# HM1030 register map
File version: 0.1
Registers are 32-bit, read-write, reset 0x0 unless marked. A register's access mark holds for its fields unless they carry their own. Offsets are from the block's base; [hi:lo] are bit positions; lines under a group give offsets from that group; {n}, {i} and the like mark numbered series.

## DMA — Registers group
Base 0x40001000
0x00 DMA_CTR — DMA使能
  [0] DMA_EN
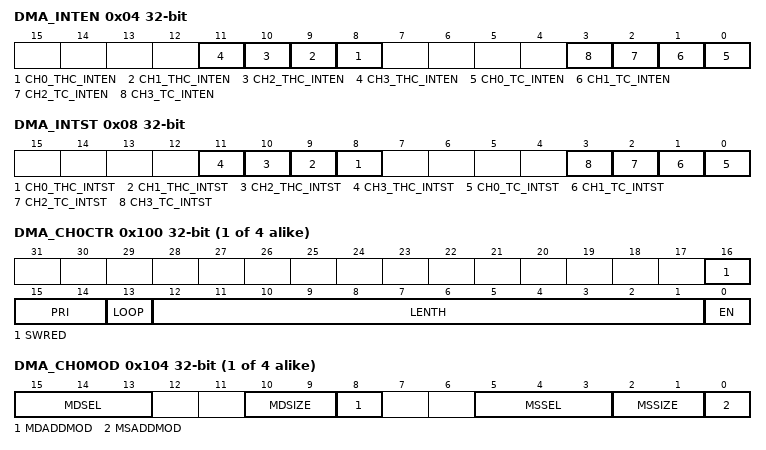
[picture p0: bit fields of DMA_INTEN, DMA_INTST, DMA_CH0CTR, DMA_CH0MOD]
0x04 DMA_INTEN — DMA中断使能
  [n+8] CH{n}_THC_INTEN (n=0..3) — 通道{n}传输一半完成中断使能寄存器
  [n] CH{n}_TC_INTEN (n=0..3) — 通道{n}传输完成中断使能寄存器
0x08 DMA_INTST — DMA中断状态
  [n+8] CH{n}_THC_INTST (n=0..3) — 通道{n}传输一半完成中断状态寄存器
  [n] CH{n}_TC_INTST (n=0..3) — 通道{n}传输完成中断状态寄存器
{0x100+0x20*i} DMA_CH{i}CTR (i=0..3) — DMA通道{i}控制寄存器
  [16] SWRED — 软件请求开始传输
  [15:14] PRI — 通道优先级
  [13] LOOP — 循环方式
  [12:1] LENTH — 传输计数
  [0] EN — 通道使能
{0x104+0x20*i} DMA_CH{i}MOD (i=0..3) — DMA通道{i}模式寄存器
  [15:13] MDSEL — MD测外设选择
  [10:9] MDSIZE — MD测总线传输宽度
  [8] MDADDMOD — MD测地址变化方式选择
  [5:3] MSSEL — MS测外设选择
  [2:1] MSSIZE — MS测总线传输宽度
  [0] MSADDMOD — MS测地址变化方式选择
{0x108+0x20*i} DMA_CH{i}MSADDR (i=0..3) — DMA通道{i}源地址寄存器
  [31:0] MSADDR — MS侧地址(源地址)
{0x10C+0x20*i} DMA_CH{i}MDADDR (i=0..3) — DMA通道{i}目标地址寄存器
  [0] MDADDR — MD侧地址(目标地址)
{0x110+0x20*i} DMA_CH{i}ST (i=0..3) — DMA通道{i}状态寄存器
  [11:0] CUR_LENTH — 当前已传输个数

## CRC — Registers group
Base 0x40003000
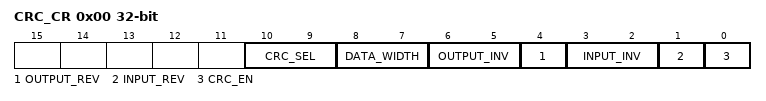
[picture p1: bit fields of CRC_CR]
0x00 CRC_CR — CRC控制
  [10:9] CRC_SEL — CRC算法选择寄存器
  [8:7] DATA_WIDTH — CRC输入数据有效位数寄存器
  [6:5] OUTPUT_INV — 输出数据翻转寄存器
  [4] OUTPUT_REV — 输出数据是否取反
  [3:2] INPUT_INV — 输入数据翻转寄存器
  [1] INPUT_REV — 输入数据是否取反
  [0] CRC_EN — CRC使能
0x04 CRC_IV — CRC初值
0x08 CRC_DATAIN — CRC输入数据寄存器
0x0C CRC_DATAOUT — CRC输出数据寄存器

## GPIOA — Registers group
Base 0x40060000
Same registers: GPIOB 0x40060800
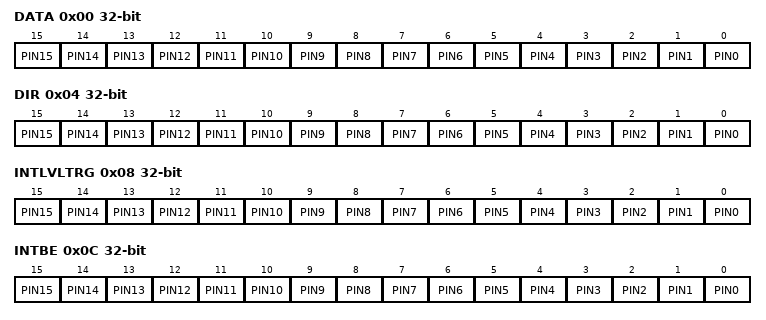
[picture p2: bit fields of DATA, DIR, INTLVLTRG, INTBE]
0x00 DATA
  [n] PIN{n} (n=0..15)
0x04 DIR — 0 输入 1 输出
  [n] PIN{n} (n=0..15)
0x08 INTLVLTRG — Interrupt Level Trigger 1 电平触发中断 0 边沿触发中断
  [n] PIN{n} (n=0..15)
0x0C INTBE — Both Edge，当INTLVLTRG设为边沿触发中断时，此位置1表示上升沿和下降沿都触发中断，置0时触发边沿由INTRISEEN选择
  [n] PIN{n} (n=0..15)
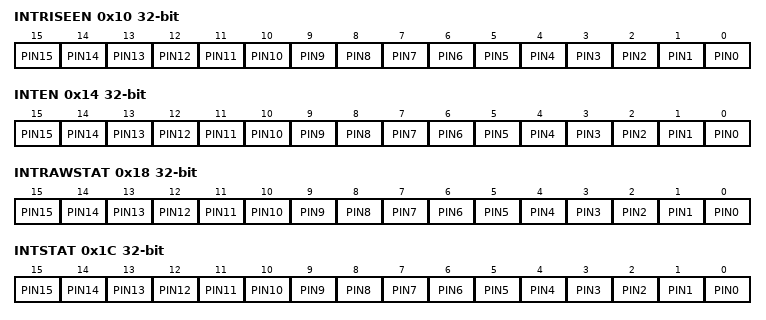
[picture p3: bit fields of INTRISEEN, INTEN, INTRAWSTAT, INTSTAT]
0x10 INTRISEEN — Interrupt Rise Edge Enable 1 上升沿/高电平触发中断 0 下降沿/低电平触发中断
  [n] PIN{n} (n=0..15)
0x14 INTEN — 1 中断使能 0 中断禁止
  [n] PIN{n} (n=0..15)
0x18 INTRAWSTAT — 中断检测单元是否检测到了触发中断的条件 1 检测到了中断触发条件 0 没有检测到中断触发条件
  [n] PIN{n} (n=0..15)
0x1C INTSTAT — INTSTAT.PIN0 = INTRAWSTAT.PIN0 and INTEN.PIN0
  [n] PIN{n} (n=0..15)
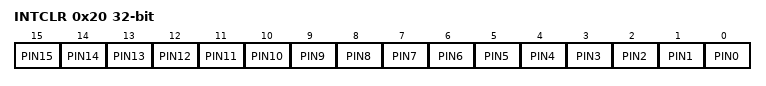
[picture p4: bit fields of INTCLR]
0x20 INTCLR — 写1清除中断标志，只对边沿触发中断有用
  [n] PIN{n} (n=0..15)

## GPIOC — Registers group
Base 0x40061000
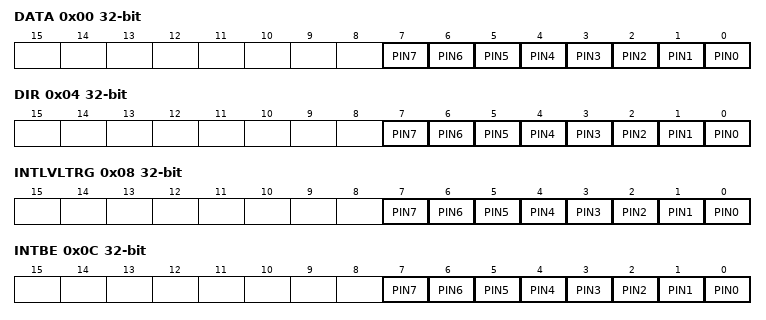
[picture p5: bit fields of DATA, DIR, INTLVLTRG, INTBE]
0x00 DATA
  [n] PIN{n} (n=0..7)
0x04 DIR — 0 输入 1 输出
  [n] PIN{n} (n=0..7)
0x08 INTLVLTRG — Interrupt Level Trigger 1 电平触发中断 0 边沿触发中断
  [n] PIN{n} (n=0..7)
0x0C INTBE — Both Edge，当INTLVLTRG设为边沿触发中断时，此位置1表示上升沿和下降沿都触发中断，置0时触发边沿由INTRISEEN选择
  [n] PIN{n} (n=0..7)
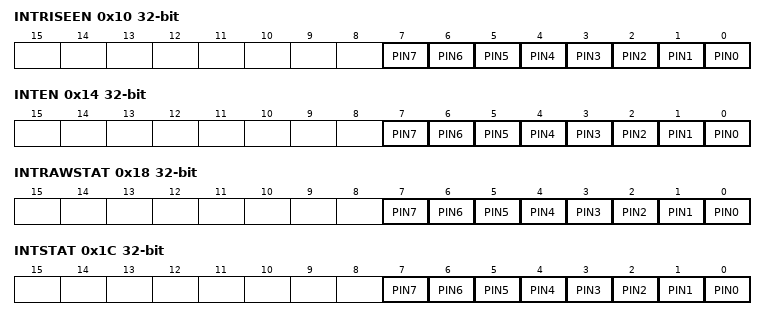
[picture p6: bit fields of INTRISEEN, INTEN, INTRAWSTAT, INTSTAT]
0x10 INTRISEEN — Interrupt Rise Edge Enable 1 上升沿/高电平触发中断 0 下降沿/低电平触发中断
  [n] PIN{n} (n=0..7)
0x14 INTEN — 1 中断使能 0 中断禁止
  [n] PIN{n} (n=0..7)
0x18 INTRAWSTAT — 中断检测单元是否检测到了触发中断的条件 1 检测到了中断触发条件 0 没有检测到中断触发条件
  [n] PIN{n} (n=0..7)
0x1C INTSTAT — INTSTAT.PIN0 = INTRAWSTAT.PIN0 and INTEN.PIN0
  [n] PIN{n} (n=0..7)
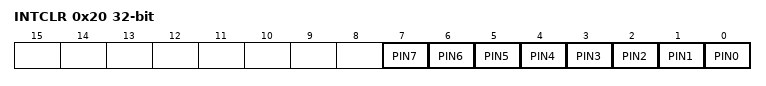
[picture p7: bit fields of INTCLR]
0x20 INTCLR — 写1清除中断标志，只对边沿触发中断有用
  [n] PIN{n} (n=0..7)

## TIMERBASE0 — Registers group
Base 0x40064000
Same registers: TIMERBASE1 0x40064800, TIMERBASE2 0x40065000
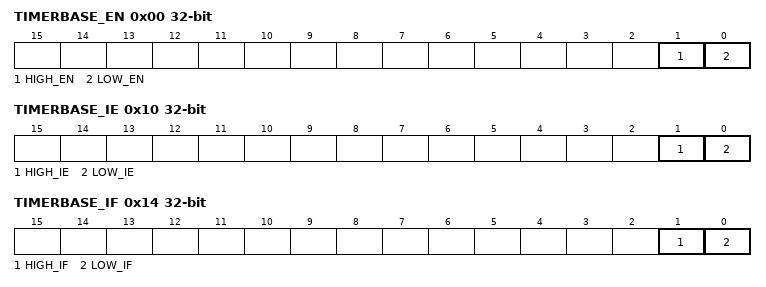
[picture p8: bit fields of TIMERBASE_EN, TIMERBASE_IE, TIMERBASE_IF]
0x00 TIMERBASE_EN — TIMERBASE使能
  [1] HIGH_EN — TIMERBASE_HIGH定时器使能寄存器
  [0] LOW_EN — TIMERBASE_LOW定时器使能寄存器
0x04 TIMERBASE_DIV — TIMERBASE预分频
  [15:0] DIV — TIMERBASE计数时钟预分频寄存器
0x10 TIMERBASE_IE — TIMERBASE定时器中断使能
  [1] HIGH_IE — TIMERBASE_HIGH定时器中断使能
  [0] LOW_IE — TIMERBASE_LOW定时器中断使能
0x14 TIMERBASE_IF — TIMERBASE定时器中断状态
  [1] HIGH_IF — TIMERBASE_HIGH定时器中断状态
  [0] LOW_IF — TIMERBASE_LOW定时器中断状态
0x20 HIGH_LOAD — TIMERBASE_HIGH定时器目标配置寄存器
  [15:0] LOAD
0x24 HIGH_CNT — TIMERBASE_HIGH定时器当前计数值
  [15:0] CNT
0x30 LOW_LOAD — TIMERBASE_LOW定时器目标配置寄存器
  [15:0] LOAD
0x34 LOW_CNT — TIMERBASE_LOW定时器当前计数值
  [15:0] CNT

## TIMERPLUS0 — Registers group
Base 0x40067000
Same registers: TIMERPLUS1 0x40067800
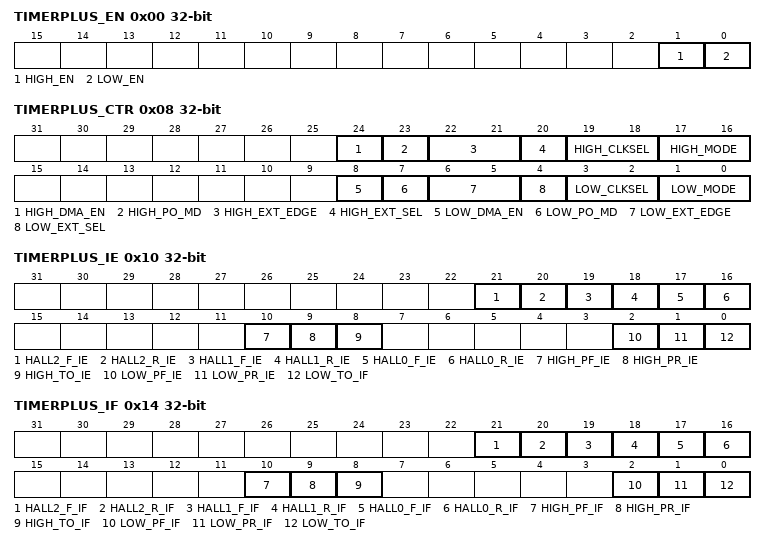
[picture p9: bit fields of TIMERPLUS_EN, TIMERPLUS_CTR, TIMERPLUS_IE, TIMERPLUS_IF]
0x00 TIMERPLUS_EN — TIMERPLUS使能
  [1] HIGH_EN — 高16bit定时器使能寄存器
  [0] LOW_EN — 低16bit定时器使能寄存器
0x04 TIMERPLUS_DIV — TIMERPLUS预分频
  [15:0] DIV — 计数时钟预分频寄存器
0x08 TIMERPLUS_CTR — TIMERPLUS配置寄存器
  [24] HIGH_DMA_EN — DMA读取TIMER_HIGH捕获值使能
  [23] HIGH_PO_MD — TIMER_HIGH周期脉冲输出使能
  [22:21] HIGH_EXT_EDGE — TIMER_HIGH计数模式或输入捕获模式输入信号有效沿选择
  [20] HIGH_EXT_SEL — TIMER_HIGH计数模式或输入捕获模式输入信号选择
  [19:18] HIGH_CLKSEL — TIMER_HIGH计数时钟源选择
  [17:16] HIGH_MODE — TIMER_HIGH工作模式寄存器
  [8] LOW_DMA_EN — DMA读取TIMER_LOW捕获值使能
  [7] LOW_PO_MD — TIMER_LOW周期脉冲输出使能
  [6:5] LOW_EXT_EDGE — TIMER_LOW计数模式或输入捕获模式输入信号有效沿选择
  [4] LOW_EXT_SEL — TIMER_LOW计数模式或输入捕获模式输入信号选择
  [3:2] LOW_CLKSEL — TIMER_LOW计数时钟源选择
  [1:0] LOW_MODE — TIMER_LOW工作模式寄存器
0x10 TIMERPLUS_IE — TIMERPLUS定时器中断使能
  [21] HALL2_F_IE — HALL2下降沿中断使能
  [20] HALL2_R_IE — HALL2上升沿中断使能
  [19] HALL1_F_IE — HALL1下降沿中断使能
  [18] HALL1_R_IE — HALL1上升沿中断使能
  [17] HALL0_F_IE — HALL0下降沿中断使能
  [16] HALL0_R_IE — HALL0上升沿中断使能
  [10] HIGH_PF_IE — TIMERPLUS_HIGH输入脉冲下降沿中断使能
  [9] HIGH_PR_IE — TIMERPLUS_HIGH输入脉冲上升沿中断使能
  [8] HIGH_TO_IE — TIMERPLUS_HIGH达到目标值中断使能
  [2] LOW_PF_IE — TIMERPLUS_LOW输入脉冲下降沿中断使能
  [1] LOW_PR_IE — TIMERPLUS_LOW输入脉冲上升沿中断使能
  [0] LOW_TO_IF — TIMERPLUS_LOW达到目标值中断使能
0x14 TIMERPLUS_IF — TIMERPLUS定时器中断状态
  [21] HALL2_F_IF — HALL2 下降沿中断状态
  [20] HALL2_R_IF — HALL2上升沿中断状态
  [19] HALL1_F_IF — HALL1下降沿中断状态
  [18] HALL1_R_IF — HALL1上升沿中断状态
  [17] HALL0_F_IF — HALL0下降沿中断状态
  [16] HALL0_R_IF — HALL0上升沿中断状态
  [10] HIGH_PF_IF — TIMERPLUS_HIGH输入脉冲下降沿中断状态
  [9] HIGH_PR_IF — TIMERPLUS_HIGH输入脉冲上升沿中断状态
  [8] HIGH_TO_IF — TIMERPLUS_HIGH达到目标值中断状态
  [2] LOW_PF_IF — TIMERPLUS_LOW输入脉冲下降沿中断状态
  [1] LOW_PR_IF — TIMERPLUS_LOW输入脉冲上升沿中断状态
  [0] LOW_TO_IF — TIMERPLUS_LOW达到目标值中断状态
0x20 HIGH_LOAD — HIGH定时器目标配置寄存器
  [15:0] LOAD
0x24 HIGH_CNT — HIGH定时器当前计数值
  [15:0] CNT
0x28 HIGH_CVAL — HIGH捕获值计数值
  [15:0] CVAL
0x30 LOW_LOAD — LOW定时器目标配置寄存器
  [15:0] LOAD
0x34 LOW_CNT — LOW定时器当前计数值
  [15:0] CNT
0x38 LOW_CVAL — LOW捕获值计数值
  [15:0] CNT
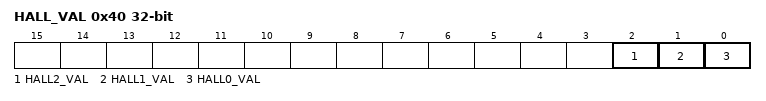
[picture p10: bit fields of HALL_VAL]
0x40 HALL_VAL — HALL原始信号电平
  [2] HALL2_VAL — HALL2的原始信号电平
  [1] HALL1_VAL — HALL1的原始信号电平
  [0] HALL0_VAL — HALL0的原始信号电平
